# cm7 register map
Registers are 32-bit, read-write, reset 0x0 unless marked. A register's access mark holds for its fields unless they carry their own. Offsets are from the block's base; [hi:lo] are bit positions; lines under a group give offsets from that group; {n}, {i} and the like mark numbered series; 'fields as' and 'values as' point back to an identical list.

## Cache — Cache maintenance operations
Base 0xE000EF50
0x00 ICIALLU wo — Instruction cache invalidate all to the PoU
0x08 ICIMVAU wo — Instruction cache invalidate by address to the PoU
0x0C DCIMVAC wo — Data cache invalidate by address to the PoC
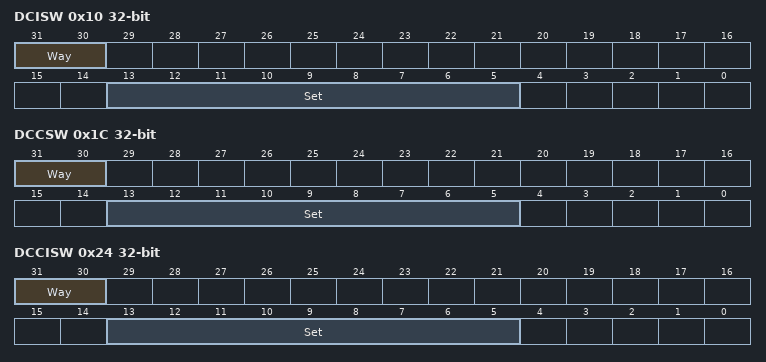
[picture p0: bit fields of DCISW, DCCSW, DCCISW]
0x10 DCISW wo — Data cache invalidate by set/way
  [31:30] Way — Way that operation applies to. For the data cache, values 0, 1, 2 and 3 are supported..
  [13:5] Set — Set/index that operation applies to. The number of indices in a cache depends on the configured cache size. When this is less than the maximum, use the LSB of this field.
0x14 DCCMVAU wo — Data cache clean by address to the PoU
0x18 DCCMVAC wo — Data cache clean by address to the PoC
0x1C DCCSW wo — Data cache clean by set/way
  fields as DCISW
0x20 DCCIMVAC wo — Data cache clean and invalidate by address to the PoC
0x24 DCCISW wo — Data cache clean and invalidate by set/way
  fields as DCISW

## Debug
Base 0xE000ED00
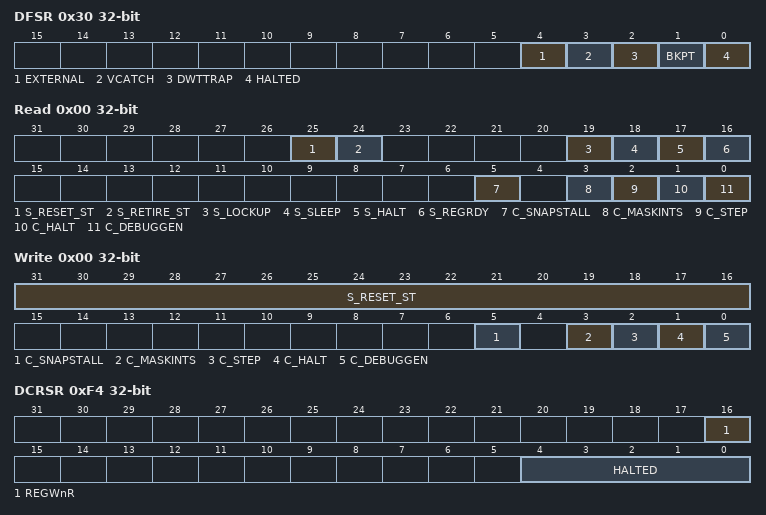
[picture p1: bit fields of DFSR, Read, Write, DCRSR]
0x30 DFSR reset not defined — Debug Fault Status Register
  [4] EXTERNAL — An asynchronous exception generated due to the assertion of EDBGRQ.
  [3] VCATCH — Vector catch triggered. Corresponding FSR will contain the primary cause of the exception.
  [2] DWTTRAP — Data Watchpoint and Trace trap. Indicates that the core halted due to at least one DWT trap event.
  [1] BKPT — BKPT instruction executed or breakpoint match in FPB.
  [0] HALTED
0xF0 DHCSR group — Debug Halting Control and Status Register
  0x00 Read ro reset not defined
    [25] S_RESET_ST, [24] S_RETIRE_ST, [19] S_LOCKUP, [18] S_SLEEP, [17] S_HALT, [16] S_REGRDY, [5] C_SNAPSTALL, [3] C_MASKINTS, [2] C_STEP, [1] C_HALT, [0] C_DEBUGGEN
  0x00 Write wo reset not defined (alternate view of DHCSR_Read)
    [31:16] S_RESET_ST — Debug Key. The value 0xA05F must be written to enable write accesses to bits [15:0], otherwise the write access will be ignored. Read behavior of bits [31:16] is as listed below.
    [5] C_SNAPSTALL
    [3] C_MASKINTS
    [2] C_STEP
    [1] C_HALT
    [0] C_DEBUGGEN
0xF4 DCRSR wo reset not defined — Debug Core Register Selector Register: The DCRSR write-only register generates a handshake to the core to transfer the selected register to/from the DCRDR. The DHCSR S_REGRDY bit is cleared when the DCRSR is written, and remains clear until the core transaction completes. This register is only accessible from Debug state.
  [16] REGWnR
    1=Write; 0=Read
  [4:0] HALTED
    {v}=Register_{v} (v=0..12); 13=Current_SP; 14=Link_Rregister; 15=Debug_Return_Address; 16=xPSR; 17=MSP; 18=PSP; 19=CONTROL_FAULTMASK_BASEPRI_PRIMASK
0xF8 DCRDR reset not defined — Debug Core Register Data Register
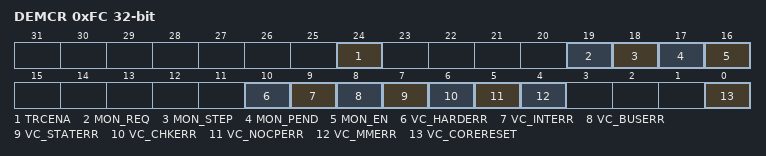
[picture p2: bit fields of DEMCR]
0xFC DEMCR reset not defined — Debug Exception and Monitor Control Register
  [24] TRCENA, [19] MON_REQ, [18] MON_STEP, [17] MON_PEND, [16] MON_EN, [10] VC_HARDERR, [9] VC_INTERR, [8] VC_BUSERR, [7] VC_STATERR, [6] VC_CHKERR, [5] VC_NOCPERR, [4] VC_MMERR, [0] VC_CORERESET

## DWT — Data Watchpoint Trace
Base 0xE0001000
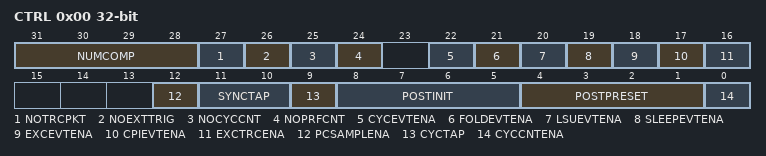
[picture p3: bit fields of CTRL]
0x00 CTRL reset not defined — Control Register
  [31:28] NUMCOMP — Number of comparators
  [27] NOTRCPKT — No trace sampling and exception tracing
  [26] NOEXTTRIG — No external match signals
  [25] NOCYCCNT — No cycle counter
  [24] NOPRFCNT — No profiling counters
  [22] CYCEVTENA — enable Cycle count event
  [21] FOLDEVTENA — enable Folded instruction count event
  [20] LSUEVTENA — enable Load Store Unit (LSU) count event
  [19] SLEEPEVTENA — enable Sleep count event
  [18] EXCEVTENA — enable interrupt overhead event
  [17] CPIEVTENA — enable CPI count event
  [16] EXCTRCENA — enable interrupt event tracing
  [12] PCSAMPLENA — enable POSTCNT as timer for PC sample packets
  [11:10] SYNCTAP — ???
  [9] CYCTAP — ???
  [8:5] POSTINIT — ???
  [4:1] POSTPRESET — ???
  [0] CYCCNTENA — enable cycle counter
0x04 CYCCNT reset not defined — Cycle Count Register
0x08 CPICNT reset not defined — CPI Count Register
0x0C EXCCNT reset not defined — Exception Overhead Count Register
0x10 SLEEPCNT reset not defined — Sleep Count Register
0x14 LSUCNT reset not defined — LSU Count Register
0x18 FOLDCNT reset not defined — Folded-instruction Count Register
0x1C PCSR ro reset not defined — Program Counter Sample Register
{0x20+0x10*i} COMP{i} reset not defined (i=0..3) — Comparator Register {i}
{0x24+0x10*i} MASK{i} reset not defined (i=0..3) — Mask Register {i}
{0x28+0x10*i} FUNCTION{i} reset not defined (i=0..3) — Function Register {i}
0xFB0 LAR wo reset not defined — Lock Access Register
0xFB4 LSR ro reset not defined — Lock Status Register

## Notices in the file
Copyright (C) 2016 AdaCore
